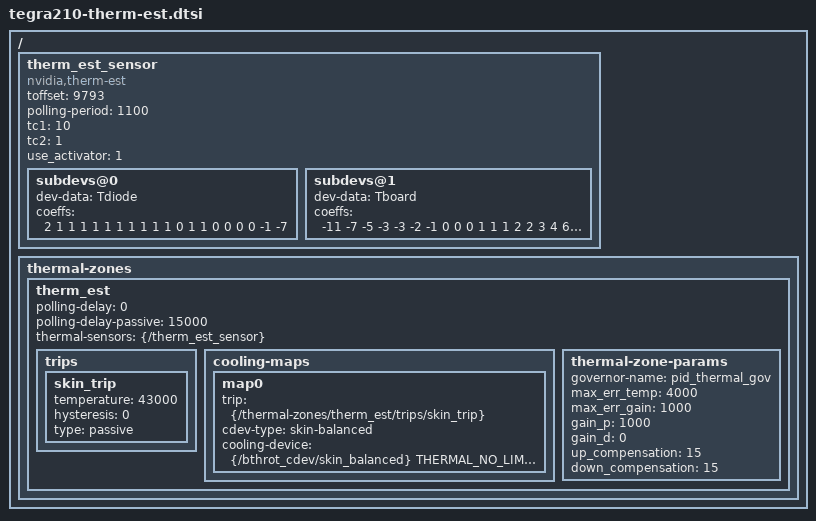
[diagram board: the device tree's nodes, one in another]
/*
 * arch/arm64/boot/dts/tegra132.dtsi
 *
 * Copyright (c) 2014, NVIDIA CORPORATION. All rights reserved.
 *
 * This program is free software; you can redistribute it and/or modify it
 * under the terms and conditions of the GNU General Public License,
 * version 2, as published by the Free Software Foundation.
 *
 * This program is distributed in the hope it will be useful, but WITHOUT
 * ANY WARRANTY; without even the implied warranty of MERCHANTABILITY or
 * FITNESS FOR A PARTICULAR PURPOSE.  See the GNU General Public License for
 * more details.
 *
 * You should have received a copy of the GNU General Public License
 * along with this program.  If not, see <http://www.gnu.org/licenses/>.
 */
#include <dt-bindings/thermal/thermal.h>

/{
	therm_est_sensor {
		compatible = "nvidia,therm-est";
		toffset = <9793>;
		polling-period = <1100>;
		tc1 = <10>;
		tc2 = <1>;
		use_activator = <1>;
		subdevs@0 {
			device_type = "therm-est-subdev";
			dev-data = "Tdiode";
			coeffs = "2 1 1 1 1 1 1 1 1 1 1 0 1 1 0 0 0 0 -1 -7";
		};
		subdevs@1 {
			device_type = "therm-est-subdev";
			dev-data = "Tboard";
			coeffs = "-11 -7 -5 -3 -3 -2 -1 0 0 0 1 1 1 2 2 3 4 6 11 18";
		};
	};
	thermal-zones {
		therm_est {
			polling-delay = <0>;
			polling-delay-passive = <15000>;

			thermal-sensors = <&{/therm_est_sensor}>;

			trips {
				skin_trip {
					temperature = <43000>;
					hysteresis = <0>;
					type = "passive";
				};
			};
			cooling-maps {
				map0 {
					trip = <&{/thermal-zones/therm_est/trips/skin_trip}>;
					cdev-type = "skin-balanced";
					cooling-device = <&{/bthrot_cdev/skin_balanced} THERMAL_NO_LIMIT THERMAL_NO_LIMIT>;
				};
			};
			thermal-zone-params {
				governor-name = "pid_thermal_gov";
				max_err_temp = <4000>;
				max_err_gain = <1000>;
				gain_p = <1000>;
				gain_d = <0>;
				up_compensation = <15>;
				down_compensation = <15>;
			};
		};
	};
};
